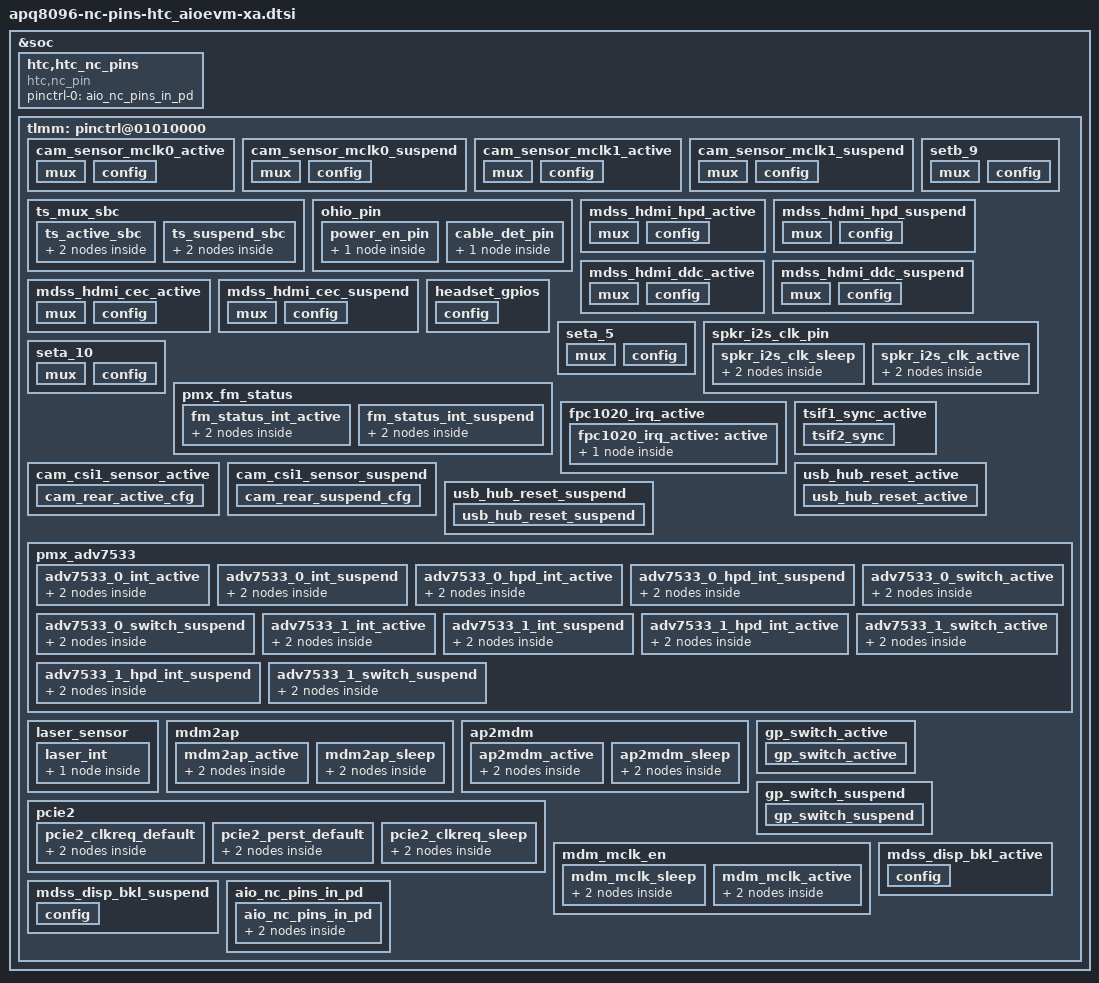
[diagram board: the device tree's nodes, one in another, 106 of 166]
/* Copyright (c) 2016, The Linux Foundation. All rights reserved.
 *
 * This program is free software; you can redistribute it and/or modify
 * it under the terms of the GNU General Public License version 2 and
 * only version 2 as published by the Free Software Foundation.
 *
 * This program is distributed in the hope that it will be useful,
 * but WITHOUT ANY WARRANTY; without even the implied warranty of
 * MERCHANTABILITY or FITNESS FOR A PARTICULAR PURPOSE.  See the
 * GNU General Public License for more details.
 */

&soc {
	htc,htc_nc_pins {
		compatible = "htc,nc_pin";

		pinctrl-names = "default";
		pinctrl-0 = <&aio_nc_pins_in_pd>;
	};
};

&tlmm {
	aio_nc_pins_in_pd {
		aio_nc_pins_in_pd: aio_nc_pins_in_pd {
			mux {
				pins = "gpio13", "gpio14", "gpio22", "gpio29", "gpio30", "gpio31", "gpio32", "gpio33", "gpio34", "gpio62", "gpio63", "gpio69", "gpio74", "gpio78", "gpio86", "gpio96", "gpio97", "gpio98", "gpio99", "gpio100", "gpio101", "gpio102", "gpio103", "gpio104", "gpio105", "gpio106", "gpio107", "gpio108", "gpio109", "gpio110", "gpio111", "gpio112", "gpio114", "gpio115", "gpio127", "gpio134", "gpio135", "gpio137", "gpio138", "gpio139", "gpio140", "gpio141", "gpio142", "gpio143", "gpio144", "gpio145", "gpio146", "gpio147", "gpio148", "gpio149";
				function = "gpio";
			};

			config {
				pins = "gpio13", "gpio14", "gpio22", "gpio29", "gpio30", "gpio31", "gpio32", "gpio33", "gpio34", "gpio62", "gpio63", "gpio69", "gpio74", "gpio78", "gpio86", "gpio96", "gpio97", "gpio98", "gpio99", "gpio100", "gpio101", "gpio102", "gpio103", "gpio104", "gpio105", "gpio106", "gpio107", "gpio108", "gpio109", "gpio110", "gpio111", "gpio112", "gpio114", "gpio115", "gpio127", "gpio134", "gpio135", "gpio137", "gpio138", "gpio139", "gpio140", "gpio141", "gpio142", "gpio143", "gpio144", "gpio145", "gpio146", "gpio147", "gpio148", "gpio149";
				drive-strength = <2>;		/* 2 mA */
				bias-pull-down;			/* PULL DOWN */
				input-enable;
			};
		};
	};
};

&soc {
	tlmm: pinctrl@01010000 {
                /* gpio13 */
                cam_sensor_mclk0_active: cam_sensor_mclk0_active {
                        mux {
				/delete-property/ pins;
                        };

                        config {
				/delete-property/ pins;
                        };
                };

                cam_sensor_mclk0_suspend: cam_sensor_mclk0_suspend {
                        mux {
				/delete-property/ pins;
                        };

                        config {
				/delete-property/ pins;
                        };
                };
                /* gpio14 */
                cam_sensor_mclk1_active: cam_sensor_mclk1_active {
                        mux {
                                /delete-property/ pins;
                        };

                        config {
                                /delete-property/ pins;
                        };
                };

                cam_sensor_mclk1_suspend: cam_sensor_mclk1_suspend {
                        mux {
                                /delete-property/ pins;
                        };

                        config {
                                /delete-property/ pins;
                        };
                };
		/* gpio22 */
                setb_9: setb_9 {
                        mux {
				/delete-property/ pins;
                        };

                        config {
				/delete-property/ pins;
                        };
                };
		/* gpio29 */
		ts_mux_sbc {
			ts_active_sbc: ts_active_sbc {
				mux {
					/delete-property/ pins;
				};

				config_sbc {
					/delete-property/ pins;
				};
		};

			ts_suspend_sbc: ts_suspend_sbc {
				mux {
					/delete-property/ pins;
				};

				config {
					/delete-property/ pins;
				};
			};
		};
		/* gpio30 */
		ohio_pin {
			power_en_pin: power_en_pin {
				config {
					/delete-property/ pins;
				};
			};
		};
		/* gpio31~gpio34 */
		mdss_hdmi_hpd_active: mdss_hdmi_hpd_active {
			mux {
				/delete-property/ pins;
			};

			config {
				/delete-property/ pins;
			};
		};

		mdss_hdmi_hpd_suspend: mdss_hdmi_hpd_suspend {
			mux {
				/delete-property/ pins;
			};

			config {
				/delete-property/ pins;
			};
		};

		mdss_hdmi_ddc_active: mdss_hdmi_ddc_active {
			mux {
				/delete-property/ pins;
			};

			config {
				/delete-property/ pins;
			};
		};

		mdss_hdmi_ddc_suspend: mdss_hdmi_ddc_suspend {
			mux {
				/delete-property/ pins;
			};

			config {
				/delete-property/ pins;
			};
		};

		mdss_hdmi_cec_active: mdss_hdmi_cec_active {
			mux {
				/delete-property/ pins;
			};

			config {
				/delete-property/ pins;
			};
		};

		mdss_hdmi_cec_suspend: mdss_hdmi_cec_suspend {
			mux {
				/delete-property/ pins;
			};

			config {
				/delete-property/ pins;
			};
		};

		/* gpio63 */
		headset_gpios: headset_gpios {
			config {
				/delete-property/ pins;
			};
		};
		seta_5: seta_5 {
			mux {
				/delete-property/ pins;
			};

			config {
				/delete-property/ pins;
			};
		};
		/* gpio69 */
		spkr_i2s_clk_pin {
			spkr_i2s_clk_sleep: spkr_i2s_clk_sleep {
				mux {
					/delete-property/ pins;
				};

				config {
					/delete-property/ pins;
				};
			};
			spkr_i2s_clk_active: spkr_i2s_clk_active {
				mux {
					/delete-property/ pins;
				};

				config {
					/delete-property/ pins;
				};
			};
		};

		/* gpio74 */
		seta_10: seta_10 {
			mux {
				/delete-property/ pins;
			};

			config {
				/delete-property/ pins;
			};
		};
		/* gpio78 */
		pmx_fm_status {
			fm_status_int_active: fm_status_int_active {
				mux {
					/delete-property/ pins;
				};

				config {
					/delete-property/ pins;
				};
			};

			fm_status_int_suspend: fm_status_int_suspend {
				mux {
					/delete-property/ pins;
				};

				config {
					/delete-property/ pins;
				};
			};
		};

		/* gpio86 */
         	fpc1020_irq_active {
			fpc1020_irq_active: active {
				config{
					/delete-property/ pins;
				};
			};
		};
		/* gpio96 */
		tsif1_sync_active: tsif1_sync_active {
			tsif2_sync {
				/delete-property/ pins;
			};
		};
		/* gpio98,gpio104 */ 
		cam_csi1_sensor_active: cam_csi1_sensor_active {
			cam_rear_active_cfg {
				/delete-property/ pins;
			};
		};

		cam_csi1_sensor_suspend: cam_csi1_sensor_suspend {
			cam_rear_suspend_cfg {
				/delete-property/ pins;
			};
		};
		/* gpio103 */
		usb_hub_reset_active: usb_hub_reset_active {
			usb_hub_reset_active {
				/delete-property/ pins;
			};
		};

		usb_hub_reset_suspend: usb_hub_reset_suspend {
			usb_hub_reset_suspend {
				/delete-property/ pins;
			};
		};
		/* gpio103 ~ gpio108 */
		pmx_adv7533: pmx_adv7533 {
			adv7533_0_int_active: adv7533_0_int_active {
				mux {
					/delete-property/ pins;
				};

				config {
					/delete-property/ pins;
				};
			};
			adv7533_0_int_suspend: adv7533_0_int_suspend {
				mux {
					/delete-property/ pins;
				};

				config {
					/delete-property/ pins;
				};
			};
			adv7533_0_hpd_int_active: adv7533_0_hpd_int_active {
				mux {
					/delete-property/ pins;
				};

				config {
					/delete-property/ pins;
				};
			};
			adv7533_0_hpd_int_suspend: adv7533_0_hpd_int_suspend {
				mux {
					/delete-property/ pins;
				};

				config {
					/delete-property/ pins;
				};
			};
			adv7533_0_switch_active: adv7533_0_switch_active {
				mux {
					/delete-property/ pins;
				};

				config {
					/delete-property/ pins;
				};
			};

			adv7533_0_switch_suspend: adv7533_0_switch_suspend {
				mux {
					/delete-property/ pins;
				};

				config {
					/delete-property/ pins;
				};
			};
			adv7533_1_int_active: adv7533_1_int_active {
				mux {
					/delete-property/ pins;
				};

				config {
					/delete-property/ pins;
				};
			};
			adv7533_1_int_suspend: adv7533_1_int_suspend {
				mux {
					/delete-property/ pins;
				};

				config {
					/delete-property/ pins;
				};
			};
			adv7533_1_hpd_int_active: adv7533_1_hpd_int_active {
				mux {
					/delete-property/ pins;
				};

				config {
					/delete-property/ pins;
				};
			};
			adv7533_1_hpd_int_suspend: adv7533_1_hpd_int_suspend {
				mux {
					/delete-property/ pins;
				};

				config {
					/delete-property/ pins;
				};
			};
			adv7533_1_switch_active: adv7533_1_switch_active {
				mux {
					/delete-property/ pins;
				};

				config {
					/delete-property/ pins;
				};
			};
			adv7533_1_switch_suspend: adv7533_1_switch_suspend {
				mux {
					/delete-property/ pins;
				};

				config {
					/delete-property/ pins;
				};
			};
		};
		/* gpio106 */
		laser_sensor {
			laser_int:laser_int {
				config {
					/delete-property/ pins;
				};
			};
		};
		mdm2ap {
			mdm2ap_active: mdm2ap_active {
				mux {
					/delete-property/ pins;
				};

				config {
					/delete-property/ pins;
				};
			};
			mdm2ap_sleep: mdm2ap_sleep {
				mux {
					/delete-property/ pins;
				};

				config {
					/delete-property/ pins;
				};
			};
		};
		/* gpio108 */
		ohio_pin {
			cable_det_pin: cable_det_pin {
				config {
					/delete-property/ pins;
				};
			};
		};
		/* gpio107,gpio109,gpio111 */
		ap2mdm {
			ap2mdm_active: ap2mdm_active {
				mux {
					/delete-property/ pins;
				};

				config {
					/delete-property/ pins;
				};
			};
			ap2mdm_sleep: ap2mdm_sleep {
				mux {
					/delete-property/ pins;
				};

				config {
					/delete-property/ pins;
				};
			};
		};
		/* gpio114~gpio115 */
		pcie2 {
			pcie2_clkreq_default: pcie2_clkreq_default {
				mux {
					/delete-property/ pins;
				};

				config {
					/delete-property/ pins;
				};
			};
			pcie2_perst_default: pcie2_perst_default {
				mux {
					/delete-property/ pins;
				};

				config {
					/delete-property/ pins;
				};
			};
			pcie2_clkreq_sleep: pcie2_clkreq_sleep {
				mux {
					/delete-property/ pins;
				};

				config {
					/delete-property/ pins;
				};
			};
		};
		/* gpio127 */
		gp_switch_active: gp_switch_active {
			gp_switch_active {
				/delete-property/ pins;
			};
		};

		gp_switch_suspend: gp_switch_suspend {
			gp_switch_suspend {
				/delete-property/ pins;
			};
		};
		/* gpio134 */
		mdm_mclk_en {
			mdm_mclk_sleep: mdm_mclk_sleep {
				mux {
					/delete-property/ pins;
				};

				config {
					/delete-property/ pins;
				};
			};
			mdm_mclk_active: mdm_mclk_active {
				mux {
					/delete-property/ pins;
				};

				config {
					/delete-property/ pins;
				};
			};
		};
		/* gpio135 */
		mdss_disp_bkl_active: mdss_disp_bkl_active {
			config {
				/delete-property/ pins;
			};
		};

		mdss_disp_bkl_suspend: mdss_disp_bkl_suspend {
			config {
				/delete-property/ pins;
			};
		};
	};
};
